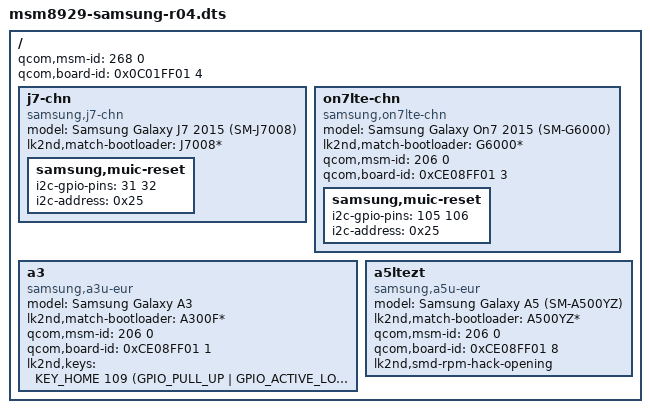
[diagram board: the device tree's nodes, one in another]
// SPDX-License-Identifier: GPL-2.0-only

/dts-v1/;

#include <skeleton.dtsi>
#include <lk2nd.h>

/ {
	// This is used by the bootloader to find the correct DTB
	qcom,msm-id = <268 0>;
	qcom,board-id = <0x0C01FF01 4>;

	j7-chn {
		model = "Samsung Galaxy J7 2015 (SM-J7008)";
		compatible = "samsung,j7-chn", "qcom,msm8929", "lk2nd,device";
		lk2nd,match-bootloader = "J7008*";
		samsung,muic-reset {
			i2c-gpio-pins = <31 32>;
			i2c-address = <0x25>;
		};
	};

	on7lte-chn {
		model = "Samsung Galaxy On7 2015 (SM-G6000)";
		compatible = "samsung,on7lte-chn", "qcom,msm8916", "lk2nd,device";
		lk2nd,match-bootloader = "G6000*";

		// The stock Samsung bootloader seems to pick <0x0C01FF01 4> as the board id as opposed to <0xCE08FF01 3>
		// This line should fix that
		qcom,msm-id = <206 0>;
		qcom,board-id = <0xCE08FF01 3>;

		samsung,muic-reset {
			i2c-gpio-pins = <105 106>;
			i2c-address = <0x25>;
		};
	};

	a3 {
		model = "Samsung Galaxy A3";
		compatible = "samsung,a3u-eur", "qcom,msm8916", "lk2nd,device";
		lk2nd,match-bootloader = "A300F*";

		qcom,msm-id = <206 0>;
		qcom,board-id = <0xCE08FF01 1>;

		lk2nd,keys = <KEY_HOME 109 (GPIO_PULL_UP | GPIO_ACTIVE_LOW)>;
	};

	a5ltezt {
		// In the downstream dts it is called Samsung A5 PROJECT Rev02
		model = "Samsung Galaxy A5 (SM-A500YZ)";
		compatible = "samsung,a5u-eur", "qcom,msm8916", "lk2nd,device";
		lk2nd,match-bootloader = "A500YZ*";

		qcom,msm-id = <206 0>;
		qcom,board-id = <0xCE08FF01 8>;
		lk2nd,smd-rpm-hack-opening;
	};
};
